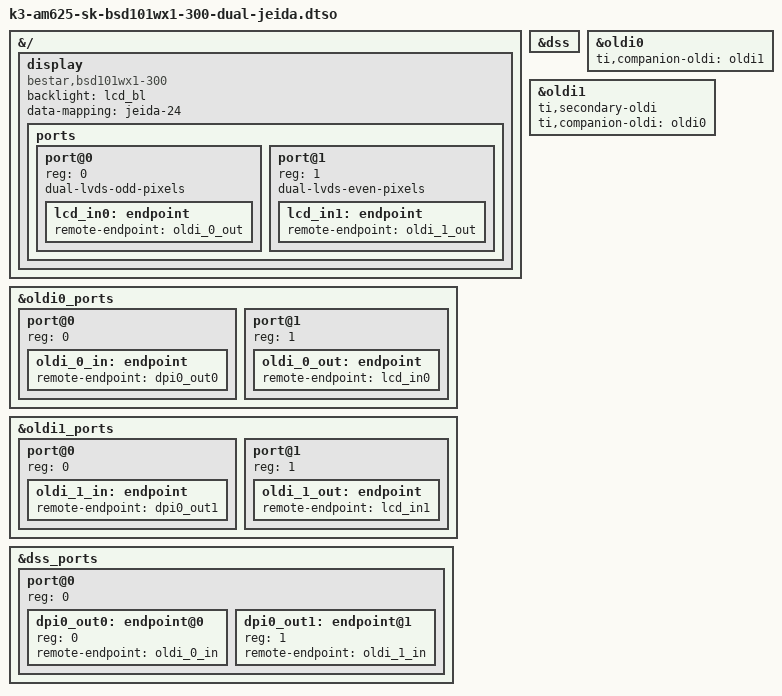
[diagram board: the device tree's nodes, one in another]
// SPDX-License-Identifier: GPL-2.0-or-later OR MIT
/* ===== CRZ TEMP bring-up variant for BSD101WX1-300: dual-link odd/even, JEIDA-24
 * Part of the LCD link/format test matrix. Select via uEnv.txt:
 *   dtbo_idx=0
 *   name_overlays=ti/k3-am625-sk-bsd101wx1-300-dual-jeida.dtbo
 * Remove unused variants once the working combination is known. ===== */
/dts-v1/;
/plugin/;

&{/} {
	display {
		compatible = "bestar,bsd101wx1-300", "panel-simple";
		backlight = <&lcd_bl>;
		data-mapping = "jeida-24";

		ports {
			#address-cells = <1>;
			#size-cells = <0>;

			port@0 {
				reg = <0>;
				dual-lvds-odd-pixels;
				lcd_in0: endpoint {
					remote-endpoint = <&oldi_0_out>;
				};
			};

			port@1 {
				reg = <1>;
				dual-lvds-even-pixels;
				lcd_in1: endpoint {
					remote-endpoint = <&oldi_1_out>;
				};
			};
		};
	};
};

&dss {
	status = "okay";
};

&oldi0 {
	status = "okay";
	ti,companion-oldi = <&oldi1>;
};

&oldi1 {
	status = "okay";
	ti,secondary-oldi;
	ti,companion-oldi = <&oldi0>;
};

&oldi0_ports {
	#address-cells = <1>;
	#size-cells = <0>;

	port@0 {
		reg = <0>;
		oldi_0_in: endpoint {
			remote-endpoint = <&dpi0_out0>;
		};
	};

	port@1 {
		reg = <1>;
		oldi_0_out: endpoint {
			remote-endpoint = <&lcd_in0>;
		};
	};
};

&oldi1_ports {
	#address-cells = <1>;
	#size-cells = <0>;

	port@0 {
		reg = <0>;
		oldi_1_in: endpoint {
			remote-endpoint = <&dpi0_out1>;
		};
	};

	port@1 {
		reg = <1>;
		oldi_1_out: endpoint {
			remote-endpoint = <&lcd_in1>;
		};
	};
};

&dss_ports {
	#address-cells = <1>;
	#size-cells = <0>;

	port@0 {
		reg = <0>;
		#address-cells = <1>;
		#size-cells = <0>;

		dpi0_out0: endpoint@0 {
			reg = <0>;
			remote-endpoint = <&oldi_0_in>;
		};

		dpi0_out1: endpoint@1 {
			reg = <1>;
			remote-endpoint = <&oldi_1_in>;
		};
	};
};
